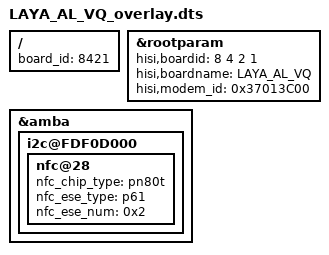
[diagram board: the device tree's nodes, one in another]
/**
 * Copyright (C) 2014 Hisilicon Ltd.
 *
 *  This program is free software; you can redistribute it and/or modify
 *  it under the terms of the GNU General Public License version 2 as
 *  publishhed by the Free Software Foundation.
 */

/dts-v1/;
/plugin/;
/include/ "LAYA_AL_VM_overlay.dtsi"
/include/ "LAYA_AL_VQ_pin.dtsi"
/include/ "LAYA_AL_VQ_modem_pin.dtsi"

/ {
    board_id = <8421>;
};

	&rootparam{
		hisi,boardid = <8 4 2 1>;
		hisi,boardname = "LAYA_AL_VQ";
		hisi,modem_id = <0x37013C00>;
	};
	&amba {
		i2c@FDF0D000 {
			nfc@28{
				nfc_chip_type = "pn80t";
				nfc_ese_type = "p61";
				nfc_ese_num = <0x2>;
			};
		};
	};

